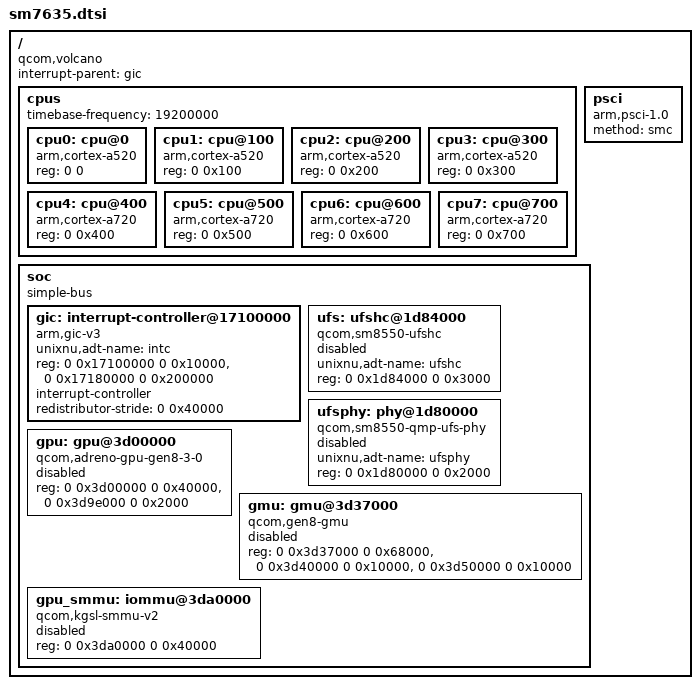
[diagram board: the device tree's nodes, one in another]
// SPDX-License-Identifier: BSD-3-Clause
// Shared SM7635 (volcano) resources, from the Nothing Phone (3a) device tree sources (NullDebris
// android_kernel_nothing_sm7635-devicetrees e0eb1dc, qcom/volcano.dtsi) and checked against a 3a's live device tree.
/ {
    compatible = "qcom,volcano";
    #address-cells = <2>;
    #size-cells = <2>;
    interrupt-parent = <&gic>;

    // volcano.dtsi:82-232: four Kryo little cores (Cortex-A520, cluster0) and four big ones (Cortex-A720, cluster1 and the
    // prime cluster2). The device tree names them qcom,kryo; the core types are from the SoC's public specification.
    cpus {
        #address-cells = <2>;
        #size-cells = <0>;
        timebase-frequency = <19200000>;
        cpu0: cpu@0 { device_type = "cpu"; compatible = "arm,cortex-a520"; reg = <0 0>; };
        cpu1: cpu@100 { device_type = "cpu"; compatible = "arm,cortex-a520"; reg = <0 0x100>; };
        cpu2: cpu@200 { device_type = "cpu"; compatible = "arm,cortex-a520"; reg = <0 0x200>; };
        cpu3: cpu@300 { device_type = "cpu"; compatible = "arm,cortex-a520"; reg = <0 0x300>; };
        cpu4: cpu@400 { device_type = "cpu"; compatible = "arm,cortex-a720"; reg = <0 0x400>; };
        cpu5: cpu@500 { device_type = "cpu"; compatible = "arm,cortex-a720"; reg = <0 0x500>; };
        cpu6: cpu@600 { device_type = "cpu"; compatible = "arm,cortex-a720"; reg = <0 0x600>; };
        cpu7: cpu@700 { device_type = "cpu"; compatible = "arm,cortex-a720"; reg = <0 0x700>; };
    };

    psci { compatible = "arm,psci-1.0"; method = "smc"; };

    soc {
        compatible = "simple-bus";
        #address-cells = <2>;
        #size-cells = <2>;
        ranges;

        gic: interrupt-controller@17100000 {
            compatible = "arm,gic-v3";
            unixnu,adt-name = "intc";
            reg = <0 0x17100000 0 0x10000>, <0 0x17180000 0 0x200000>;
            #interrupt-cells = <4>;
            #address-cells = <0>;
            interrupt-controller;
            redistributor-stride = <0 0x40000>;
        };

        // The UFS host and PHY windows equal SM8550's, so NativeUfs matches the same compatible.
        ufs: ufshc@1d84000 {
            compatible = "qcom,sm8550-ufshc";
            unixnu,adt-name = "ufshc";
            reg = <0 0x1d84000 0 0x3000>;
            status = "disabled";
        };

        ufsphy: phy@1d80000 {
            compatible = "qcom,sm8550-qmp-ufs-phy";
            unixnu,adt-name = "ufsphy";
            reg = <0 0x1d80000 0 0x2000>;
            status = "disabled";
        };

        // Adreno 810 (gen8): kgsl_3d0_reg_memory, cx_misc, the GMU and its AO block, RSCC and the GPU's SMMU. The board's GPU
        // driver takes these from board.toml [gpu]; the nodes record them and stay disabled.
        gpu: gpu@3d00000 {
            compatible = "qcom,adreno-gpu-gen8-3-0";
            reg = <0 0x3d00000 0 0x40000>, <0 0x3d9e000 0 0x2000>;
            reg-names = "kgsl_3d0_reg_memory", "cx_misc";
            status = "disabled";
        };

        gmu: gmu@3d37000 {
            compatible = "qcom,gen8-gmu";
            reg = <0 0x3d37000 0 0x68000>, <0 0x3d40000 0 0x10000>, <0 0x3d50000 0 0x10000>;
            reg-names = "gmu", "gmu_ao_blk_dec0", "rscc";
            status = "disabled";
        };

        gpu_smmu: iommu@3da0000 {
            compatible = "qcom,kgsl-smmu-v2";
            reg = <0 0x3da0000 0 0x40000>;
            status = "disabled";
        };
    };
};
